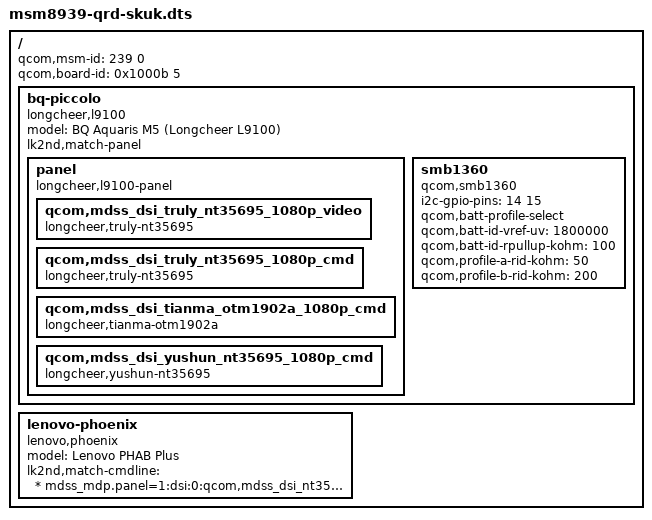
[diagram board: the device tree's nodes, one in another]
// SPDX-License-Identifier: GPL-2.0-only

/dts-v1/;

#include <skeleton.dtsi>

/ {
	qcom,msm-id = <239 0>;
	qcom,board-id = <0x1000b 5>;

	bq-piccolo {
		model = "BQ Aquaris M5 (Longcheer L9100)";
		compatible = "longcheer,l9100", "qcom,msm8939", "lk2nd,device";
		lk2nd,match-panel;

		panel {
			compatible = "longcheer,l9100-panel";

			qcom,mdss_dsi_truly_nt35695_1080p_video {
				compatible = "longcheer,truly-nt35695";
			};
			qcom,mdss_dsi_truly_nt35695_1080p_cmd {
				compatible = "longcheer,truly-nt35695";
			};
			qcom,mdss_dsi_tianma_otm1902a_1080p_cmd {
				compatible = "longcheer,tianma-otm1902a";
			};
			qcom,mdss_dsi_yushun_nt35695_1080p_cmd {
				compatible = "longcheer,yushun-nt35695";
			};
		};

		smb1360 {
			compatible = "qcom,smb1360";
			i2c-gpio-pins = <14 15>;

			qcom,batt-profile-select;
			qcom,batt-id-vref-uv = <1800000>;
			qcom,batt-id-rpullup-kohm = <100>;
			qcom,profile-a-rid-kohm = <50>;
			qcom,profile-b-rid-kohm = <200>;
		};
	};

	lenovo-phoenix {
		model = "Lenovo PHAB Plus";
		compatible = "lenovo,phoenix", "qcom,msm8939", "lk2nd,device";
		lk2nd,match-cmdline = "* mdss_mdp.panel=1:dsi:0:qcom,mdss_dsi_nt35532_1080p_skuk_video:1:none*";
	};
};
